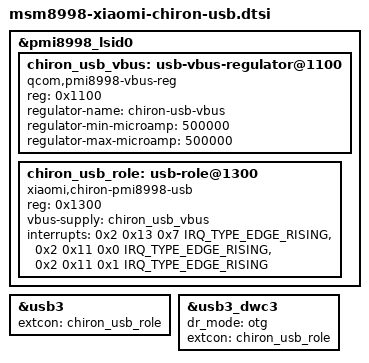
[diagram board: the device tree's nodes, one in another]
// SPDX-License-Identifier: BSD-3-Clause
/* Passive USB2 OTG only; the existing charger and USB3 PHY remain unchanged. */
&pmi8998_lsid0 {
	chiron_usb_vbus: usb-vbus-regulator@1100 {
		compatible = "qcom,pmi8998-vbus-reg";
		reg = <0x1100>;
		regulator-name = "chiron-usb-vbus";
		regulator-min-microamp = <500000>;
		regulator-max-microamp = <500000>;
	};

	chiron_usb_role: usb-role@1300 {
		compatible = "xiaomi,chiron-pmi8998-usb";
		reg = <0x1300>;
		vbus-supply = <&chiron_usb_vbus>;
		interrupts = <0x2 0x13 0x7 IRQ_TYPE_EDGE_RISING>,
					 <0x2 0x11 0x0 IRQ_TYPE_EDGE_RISING>,
					 <0x2 0x11 0x1 IRQ_TYPE_EDGE_RISING>;
		interrupt-names = "type-c-change", "otg-fail", "otg-oc";
	};
};

&usb3 {
	extcon = <&chiron_usb_role>;
};

&usb3_dwc3 {
	dr_mode = "otg";
	extcon = <&chiron_usb_role>;
};
